# DSS_CTRL register map
Vendor: Texas Instruments
Peripheral module from a debugger description file (folder awr29xx).
Registers are 32-bit, read-only, no defined reset value unless marked. A register's access mark holds for its fields unless they carry their own. Offsets are as the file gives them; lines under a group give offsets from that group; [hi:lo] are bit positions; {n}, {i} and the like mark numbered series; 'fields as' and 'values as' point back to an identical list; <NAME> marks a mode.

## DSS_CTRL (part 1 of 2)
0xC8 DSS_TPCC_A_PARITY_STATUS
  [7:0] parity_addr — TPCC Error Address at which Parity Error occurred
0xCC DSS_TPCC_B_PARITY_STATUS
  fields as DSS_TPCC_A_PARITY_STATUS
0xD0 DSS_TPCC_C_PARITY_STATUS
  [8:0] parity_addr — TPCC Error Address at which Parity Error occurred
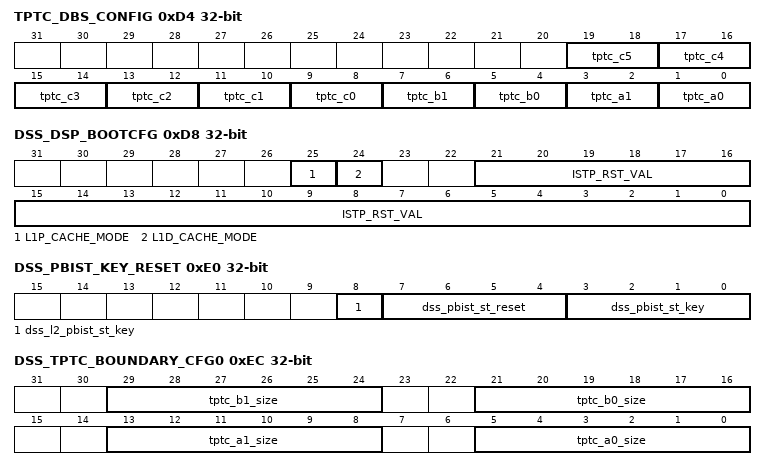
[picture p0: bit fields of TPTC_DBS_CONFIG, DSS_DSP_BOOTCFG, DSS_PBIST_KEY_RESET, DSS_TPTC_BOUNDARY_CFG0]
0xD4 TPTC_DBS_CONFIG rw
  [2n+9:2n+8] tptc_c{n} (n=0..5) — Max Burst size tieoff value for TPTC C{n}
  [7:6] tptc_b1 — Max Burst size tieoff value for TPTC B0
  [5:4] tptc_b0 — Max Burst size tieoff value for TPTC B0
  [3:2] tptc_a1 — Max Burst size tieoff value for TPTC A1
  [1:0] tptc_a0 — Max Burst size tieoff value for TPTC A0
0xD8 DSS_DSP_BOOTCFG rw
  [25] L1P_CACHE_MODE — DSP Boot Configuration : L1P Cache Mode
  [24] L1D_CACHE_MODE — DSP Boot Configuration : L1D Cache Mode
  [21:0] ISTP_RST_VAL — DSP Boot Configuration : Reset Vector
0xDC DSS_DSP_NMI_GATE rw
  [2:0] gate — Write 3'b111 to gate the Non Maskable Interrupt to the DSP. This is not expected to be used
0xE0 DSS_PBIST_KEY_RESET rw
  [8] dss_l2_pbist_st_key — DSS L2 PBIST Selftest Key.
  [7:4] dss_pbist_st_reset — DSS PBIST controller will be brought out of reset when value is 0xA
  [3:0] dss_pbist_st_key — DSS PBIST Selftest Key. Valid value is 0x5
0xE4 DSS_PBIST_REG0 rw
  [31:0] dss_pbist_reg0 — DSP PBIST registers
0xE8 DSS_PBIST_REG1 rw
  [31:0] dss_pbist_reg1 — DSP PBIST registers
0xEC DSS_TPTC_BOUNDARY_CFG0 rw
  [29:24] tptc_b1_size — 6 bit signal used for deciding the boundary crossing size for CID-RID-SID reordering of TPTC Example: writing 6'd19 decidies boundary to be 2^19 i.e. 512 KB
  [21:16] tptc_b0_size — 6 bit signal used for deciding the boundary crossing size for CID-RID-SID reordering of TPTC Example: writing 6'd19 decidies boundary to be 2^19 i.e. 512 KB
  [13:8] tptc_a1_size — 6 bit signal used for deciding the boundary crossing size for CID-RID-SID reordering of TPTC Example: writing 6'd19 decidies boundary to be 2^19 i.e. 512 KB
  [5:0] tptc_a0_size — 6 bit signal used for deciding the boundary crossing size for CID-RID-SID reordering of TPTC Example: writing 6'd19 decidies boundary to be 2^19 i.e. 512 KB
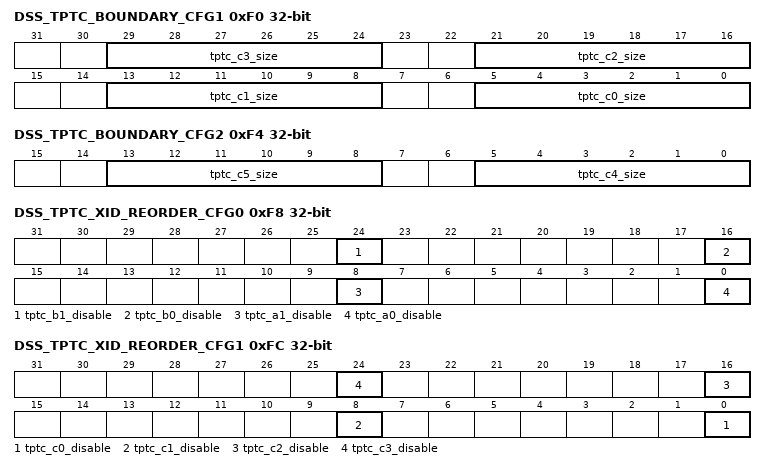
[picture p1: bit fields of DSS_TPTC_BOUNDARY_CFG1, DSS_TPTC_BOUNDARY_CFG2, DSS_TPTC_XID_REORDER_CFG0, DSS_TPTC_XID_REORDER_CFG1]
0xF0 DSS_TPTC_BOUNDARY_CFG1 rw
  [8n+5:8n] tptc_c{n}_size (n=0..3) — 6 bit signal used for deciding the boundary crossing size for CID-RID-SID reordering of TPTC Example: writing 6'd19 decidies boundary to be 2^19 i.e. 512 KB
0xF4 DSS_TPTC_BOUNDARY_CFG2 rw
  [13:8] tptc_c5_size — 6 bit signal used for deciding the boundary crossing size for CID-RID-SID reordering of TPTC Example: writing 6'd19 decidies boundary to be 2^19 i.e. 512 KB
  [5:0] tptc_c4_size — 6 bit signal used for deciding the boundary crossing size for CID-RID-SID reordering of TPTC Example: writing 6'd19 decidies boundary to be 2^19 i.e. 512 KB
0xF8 DSS_TPTC_XID_REORDER_CFG0 rw
  [24] tptc_b1_disable — Writing 1'b1 will disable the CID-RID-SID reodering feature for the TPTC instance
  [16] tptc_b0_disable — Writing 1'b1 will disable the CID-RID-SID reodering feature for the TPTC instance
  [8] tptc_a1_disable — Writing 1'b1 will disable the CID-RID-SID reodering feature for the TPTC instance
  [0] tptc_a0_disable — Writing 1'b1 will disable the CID-RID-SID reodering feature for the TPTC instance
0xFC DSS_TPTC_XID_REORDER_CFG1 rw
  [8n] tptc_c{n}_disable (n=0..3) — Writing 1'b1 will disable the CID-RID-SID reodering feature for the TPTC instance
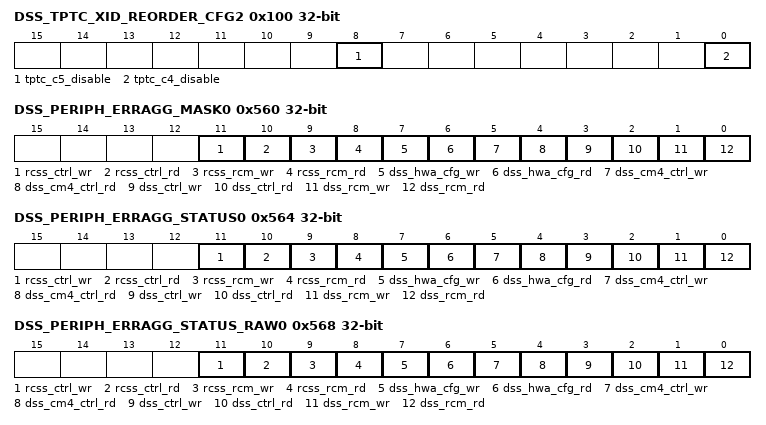
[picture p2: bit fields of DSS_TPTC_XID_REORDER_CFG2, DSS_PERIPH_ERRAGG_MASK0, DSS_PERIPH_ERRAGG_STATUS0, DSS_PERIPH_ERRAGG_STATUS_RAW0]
0x100 DSS_TPTC_XID_REORDER_CFG2 rw
  [8] tptc_c5_disable — Writing 1'b1 will disable the CID-RID-SID reodering feature for the TPTC instance
  [0] tptc_c4_disable — Writing 1'b1 will disable the CID-RID-SID reodering feature for the TPTC instance
{0x108+4i} ESM_GATING{i} rw (i=0..3)
  [31:0] esm_gating — Bit3:0 : writing '000' will ungate the DSS ESM Group2 Error {8i} Bit7:4 : writing '000' will ungate the DSS ESM Group2 Error {8i+1} Bit31:28 : writing '000' will ungate the DSS ESM Group2 Error {8i+7}
0x560 DSS_PERIPH_ERRAGG_MASK0 rw
  [11] rcss_ctrl_wr — Mask the Write error from RCSS_CTRL space from generating an error DSS_PERIPH_ERRAGG to the Processor
  [10] rcss_ctrl_rd — Mask the Read error from RCSS_CTRL space from generating an error DSS_PERIPH_ERRAGG to the Processor
  [9] rcss_rcm_wr — Mask the Write error from RCSS_RCM space from generating an error DSS_PERIPH_ERRAGG to the Processor
  [8] rcss_rcm_rd — Mask the Read error from RCSS_RCM space from generating an error DSS_PERIPH_ERRAGG to the Processor
  [7] dss_hwa_cfg_wr — Mask the Write error from DSS_HWA_CFG space from generating an error DSS_PERIPH_ERRAGG to the Processor
  [6] dss_hwa_cfg_rd — Mask the Read error from DSS_HWA_CFG space from generating an error DSS_PERIPH_ERRAGG to the Processor
  [5] dss_cm4_ctrl_wr — Mask the Write error from DSS_CM4_CTRL space from generating an error DSS_PERIPH_ERRAGG to the Processor
  [4] dss_cm4_ctrl_rd — Mask the Read error from DSS_CM4_CTRL space from generating an error DSS_PERIPH_ERRAGG to the Processor
  [3] dss_ctrl_wr — Mask the Write error from DSS_CTRL space from generating an error DSS_PERIPH_ERRAGG to the Processor
  [2] dss_ctrl_rd — Mask the Read error from DSS_CTRL space from generating an error DSS_PERIPH_ERRAGG to the Processor
  [1] dss_rcm_wr — Mask the Write error from DSS_RCM space from generating an error DSS_PERIPH_ERRAGG to the Processor
  [0] dss_rcm_rd — Mask the Read error from DSS_RCM space from generating an error DSS_PERIPH_ERRAGG to the Processor
0x564 DSS_PERIPH_ERRAGG_STATUS0 rw
  [11] rcss_ctrl_wr — Status of the Write error from RCSS_CTRL space. Read 1 : Read error occurred on access to the RCSS_CTRL space
  [10] rcss_ctrl_rd — Status of the Read error from RCSS_CTRL space. Read 1 : Read error occurred on access to the RCSS_CTRL space
  [9] rcss_rcm_wr — Status of the Write error from RCSS_RCM space. Read 1 : Read error occurred on access to the RCSS_RCM space
  [8] rcss_rcm_rd — Status of the Read error from RCSS_RCM space. Read 1 : Read error occurred on access to the RCSS_RCM space
  [7] dss_hwa_cfg_wr — Status of the Write error from DSS_HWA_CFG space. Read 1 : Read error occurred on access to the DSS_HWA_CFG space
  [6] dss_hwa_cfg_rd — Status of the Read error from DSS_HWA_CFG space. Read 1 : Read error occurred on access to the DSS_HWA_CFG space
  [5] dss_cm4_ctrl_wr — Status of the Write error from DSS_CM4_CTRL space. Read 1 : Read error occurred on access to the DSS_CM4_CTRL space
  [4] dss_cm4_ctrl_rd — Status of the Read error from DSS_CM4_CTRL space. Read 1 : Read error occurred on access to the DSS_CM4_CTRL space
  [3] dss_ctrl_wr — Status of the Write error from DSS_CTRL space. Read 1 : Read error occurred on access to the DSS_CTRL space
  [2] dss_ctrl_rd — Status of the Read error from DSS_CTRL space. Read 1 : Read error occurred on access to the DSS_CTRL space
  [1] dss_rcm_wr — Status of the Write error from DSS_RCM space. Read 1 : Read error occurred on access to the DSS_RCM space
  [0] dss_rcm_rd — Status of the Read error from DSS_RCM space. Read 1 : Read error occurred on access to the DSS_RCM space
0x568 DSS_PERIPH_ERRAGG_STATUS_RAW0 rw
  [11] rcss_ctrl_wr — Raw Status of the Write error from RCSS_CTRL space irrespective of it being masked. Read 1 : Read error occurred on access to the RCSS_CTRL space
  [10] rcss_ctrl_rd — Raw Status of the Read error from RCSS_CTRL space irrespective of it being masked. Read 1 : Read error occurred on access to the RCSS_CTRL space
  [9] rcss_rcm_wr — Raw Status of the Write error from RCSS_RCM space irrespective of it being masked. Read 1 : Read error occurred on access to the RCSS_RCM space
  [8] rcss_rcm_rd — Raw Status of the Read error from RCSS_RCM space irrespective of it being masked. Read 1 : Read error occurred on access to the RCSS_RCM space
  [7] dss_hwa_cfg_wr — Raw Status of the Write error from DSS_HWA_CFG space irrespective of it being masked. Read 1 : Read error occurred on access to the DSS_HWA_CFG space
  [6] dss_hwa_cfg_rd — Raw Status of the Read error from DSS_HWA_CFG space irrespective of it being masked. Read 1 : Read error occurred on access to the DSS_HWA_CFG space
  [5] dss_cm4_ctrl_wr — Raw Status of the Write error from DSS_CM4_CTRL space irrespective of it being masked. Read 1 : Read error occurred on access to the DSS_CM4_CTRL space
  [4] dss_cm4_ctrl_rd — Raw Status of the Read error from DSS_CM4_CTRL space irrespective of it being masked. Read 1 : Read error occurred on access to the DSS_CM4_CTRL space
  [3] dss_ctrl_wr — Raw Status of the Write error from DSS_CTRL space irrespective of it being masked. Read 1 : Read error occurred on access to the DSS_CTRL space
  [2] dss_ctrl_rd — Raw Status of the Read error from DSS_CTRL space irrespective of it being masked. Read 1 : Read error occurred on access to the DSS_CTRL space
  [1] dss_rcm_wr — Raw Status of the Write error from DSS_RCM space irrespective of it being masked. Read 1 : Read error occurred on access to the DSS_RCM space
  [0] dss_rcm_rd — Raw Status of the Read error from DSS_RCM space irrespective of it being masked. Read 1 : Read error occurred on access to the DSS_RCM space
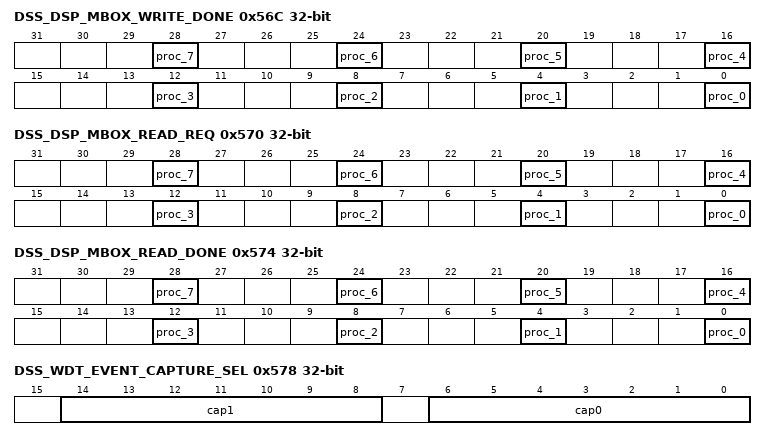
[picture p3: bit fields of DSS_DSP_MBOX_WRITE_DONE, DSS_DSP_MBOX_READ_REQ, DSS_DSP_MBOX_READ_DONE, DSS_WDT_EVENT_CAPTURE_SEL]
0x56C DSS_DSP_MBOX_WRITE_DONE rw
  [28] proc_7 — Write pulse bit field:This register should be written once finishing writing into the mailbox memory of processor 7
  [4n] proc_{n} (n=0..6) — Write pulse bit field: This register should be written once finishing writing into the mailbox memory of processor {n}
0x570 DSS_DSP_MBOX_READ_REQ rw
  [4n] proc_{n} (n=0..7) — This is request from processor {n} to DSS_DSP. Requesting it to read from mailbox.
0x574 DSS_DSP_MBOX_READ_DONE rw
  [4n] proc_{n} (n=0..7) — This register should be written once finishing reading from DSS_DSP's mailbox written by proc {n}
0x578 DSS_WDT_EVENT_CAPTURE_SEL rw
  [14:8] cap1 — Select the DSS_WDT Capture Event 1 from the DSS DSP Interrupt Map
  [6:0] cap0 — Select the DSS_WDT Capture Event 0 from the DSS DSP Interrupt Map
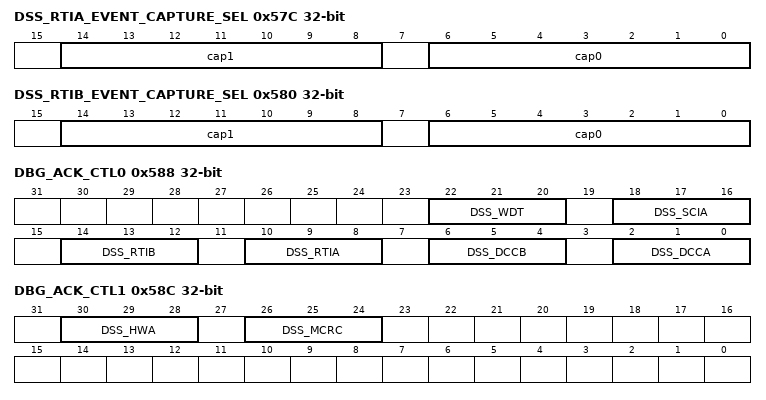
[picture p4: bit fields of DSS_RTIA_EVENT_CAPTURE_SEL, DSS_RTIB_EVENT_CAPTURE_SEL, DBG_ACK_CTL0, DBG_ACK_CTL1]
0x57C DSS_RTIA_EVENT_CAPTURE_SEL rw
  [14:8] cap1 — Select the DSS_RTIA Capture Event 1 from the DSS DSP Interrupt Map
  [6:0] cap0 — Select the DSS_RTIA Capture Event 0 from the DSS DSP Interrupt Map
0x580 DSS_RTIB_EVENT_CAPTURE_SEL rw
  [14:8] cap1 — Select the DSS_RTIB Capture Event 1 from the DSS DSP Interrupt Map
  [6:0] cap0 — Select the DSS_RTIB Capture Event 0 from the DSS DSP Interrupt Map
0x584 DBG_ACK_CPU_CTRL rw
  [0] sel — Select the Processor Suspend that is used to Suspend the DSS Peripehrals 0: DSP 1:MSS CR5
0x588 DBG_ACK_CTL0 rw
  [22:20] DSS_WDT — Enable Suspend control for the peripheral. 0 :Peripheral not suspended along with processor 1: Peripehal Suspended along with procesor
  [18:16] DSS_SCIA — Enable Suspend control for the peripheral. 0 :Peripheral not suspended along with processor 1: Peripehal Suspended along with procesor
  [14:12] DSS_RTIB — Enable Suspend control for the peripheral. 0 :Peripheral not suspended along with processor 1: Peripehal Suspended along with procesor
  [10:8] DSS_RTIA — Enable Suspend control for the peripheral. 0 :Peripheral not suspended along with processor 1: Peripehal Suspended along with procesor
  [6:4] DSS_DCCB — Enable Suspend control for the peripheral. 0 :Peripheral not suspended along with processor 1: Peripehal Suspended along with procesor
  [2:0] DSS_DCCA — Enable Suspend control for the peripheral. 0 :Peripheral not suspended along with processor 1: Peripehal Suspended along with procesor
0x58C DBG_ACK_CTL1 rw
  [30:28] DSS_HWA — Enable Suspend control for the peripheral. 0 :Peripheral not suspended along with processor 1: Peripehal Suspended along with procesor
  [26:24] DSS_MCRC — Enable Suspend control for the peripheral. 0 :Peripheral not suspended along with processor 1: Peripehal Suspended along with procesor
0x590 DSS_DSP_INT_SEL rw
  [2:0] RCSS_CSI2_ICSSM — DSS DSP Interrupt selcet 0x0: CSI2 Interrupts are propagated to DSP 0x7 : ICSSM Interrupts are propagted to DSP
0x594 DSS_CBUFF_TRIGGER_SEL rw
  [6:0] sel — DSS CBUFF HW Trigger select from DSS DSP Interrupt Map. Reset value selects RSS_ADC_CAPTURE_COMPLETE as cbuff trigger
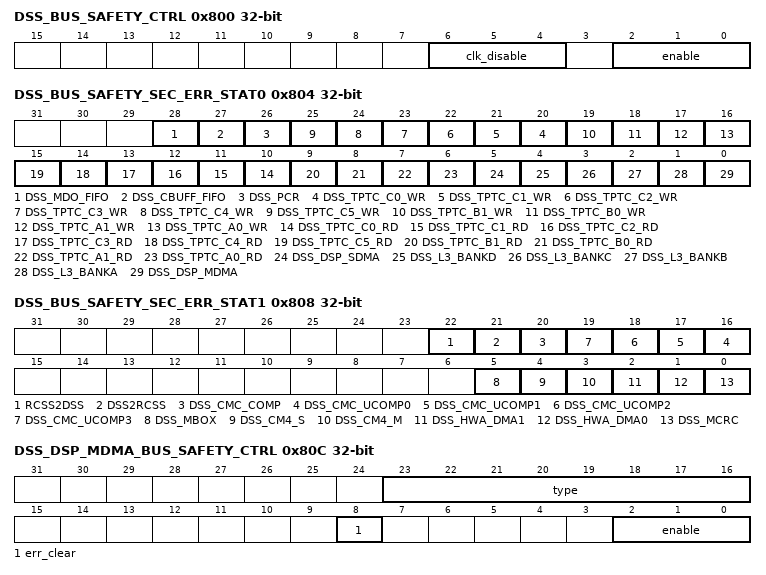
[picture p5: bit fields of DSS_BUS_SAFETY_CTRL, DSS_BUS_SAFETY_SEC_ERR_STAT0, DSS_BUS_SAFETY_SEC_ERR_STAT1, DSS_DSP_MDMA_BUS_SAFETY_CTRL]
0x800 DSS_BUS_SAFETY_CTRL rw
  [6:4] clk_disable — Option to clock gate the safety infrastructure is Safety is disabled
  [2:0] enable — Refer to TPR12 Substem Microarch document for more details
0x804 DSS_BUS_SAFETY_SEC_ERR_STAT0
  [28] DSS_MDO_FIFO — Refer to TPR12 Substem Microarch document for more details
  [27] DSS_CBUFF_FIFO — Refer to TPR12 Substem Microarch document for more details
  [26] DSS_PCR — Refer to TPR12 Substem Microarch document for more details
  [n+20] DSS_TPTC_C{n}_WR (n=0..5) — Refer to TPR12 Substem Microarch document for more details
  [19] DSS_TPTC_B1_WR — Refer to TPR12 Substem Microarch document for more details
  [18] DSS_TPTC_B0_WR — Refer to TPR12 Substem Microarch document for more details
  [17] DSS_TPTC_A1_WR — Refer to TPR12 Substem Microarch document for more details
  [16] DSS_TPTC_A0_WR — Refer to TPR12 Substem Microarch document for more details
  [n+10] DSS_TPTC_C{n}_RD (n=0..5) — Refer to TPR12 Substem Microarch document for more details
  [9] DSS_TPTC_B1_RD — Refer to TPR12 Substem Microarch document for more details
  [8] DSS_TPTC_B0_RD — Refer to TPR12 Substem Microarch document for more details
  [7] DSS_TPTC_A1_RD — Refer to TPR12 Substem Microarch document for more details
  [6] DSS_TPTC_A0_RD — Refer to TPR12 Substem Microarch document for more details
  [5] DSS_DSP_SDMA — Refer to TPR12 Substem Microarch document for more details
  [4] DSS_L3_BANKD — Refer to TPR12 Substem Microarch document for more details
  [3] DSS_L3_BANKC — Refer to TPR12 Substem Microarch document for more details
  [2] DSS_L3_BANKB — Refer to TPR12 Substem Microarch document for more details
  [1] DSS_L3_BANKA — Refer to TPR12 Substem Microarch document for more details
  [0] DSS_DSP_MDMA — Refer to TPR12 Substem Microarch document for more details
0x808 DSS_BUS_SAFETY_SEC_ERR_STAT1
  [22] RCSS2DSS — Refer to TPR12 Substem Microarch document for more details
  [21] DSS2RCSS — Refer to TPR12 Substem Microarch document for more details
  [20] DSS_CMC_COMP — Refer to TPR12 Substem Microarch document for more details
  [n+16] DSS_CMC_UCOMP{n} (n=0..3) — Refer to TPR12 Substem Microarch document for more details
  [5] DSS_MBOX — Refer to TPR12 Substem Microarch document for more details
  [4] DSS_CM4_S — Refer to TPR12 Substem Microarch document for more details
  [3] DSS_CM4_M — Refer to TPR12 Substem Microarch document for more details
  [2] DSS_HWA_DMA1 — Refer to TPR12 Substem Microarch document for more details
  [1] DSS_HWA_DMA0 — Refer to TPR12 Substem Microarch document for more details
  [0] DSS_MCRC — Refer to TPR12 Substem Microarch document for more details
0x80C DSS_DSP_MDMA_BUS_SAFETY_CTRL access per field
  [23:16] type ro — Refer to TPR12 Substem Microarch document for more details
  [8] err_clear rw — Refer to TPR12 Substem Microarch document for more details
  [2:0] enable rw — Refer to TPR12 Substem Microarch document for more details
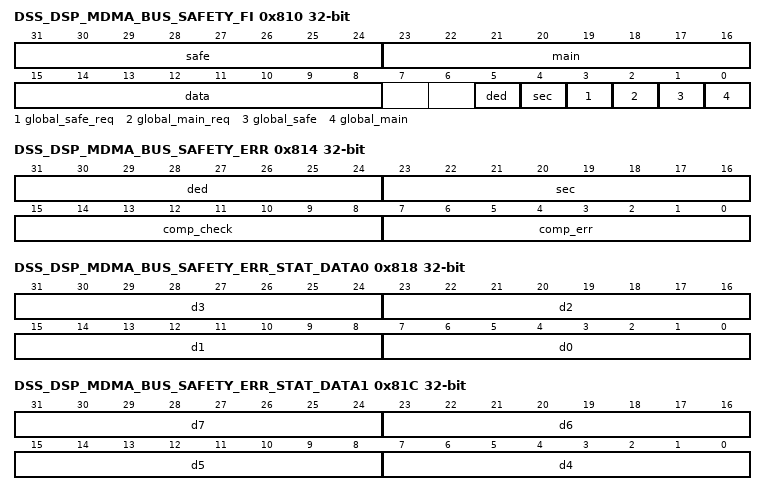
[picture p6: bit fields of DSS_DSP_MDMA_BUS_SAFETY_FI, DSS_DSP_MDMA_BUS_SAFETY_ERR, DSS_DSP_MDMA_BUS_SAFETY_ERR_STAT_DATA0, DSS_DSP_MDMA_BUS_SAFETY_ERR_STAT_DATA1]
0x810 DSS_DSP_MDMA_BUS_SAFETY_FI rw
  [31:24] safe — Refer to TPR12 Substem Microarch document for more details
  [23:16] main — Refer to TPR12 Substem Microarch document for more details
  [15:8] data — Refer to TPR12 Substem Microarch document for more details
  [5] ded — Refer to TPR12 Substem Microarch document for more details
  [4] sec — Refer to TPR12 Substem Microarch document for more details
  [3] global_safe_req — Refer to TPR12 Substem Microarch document for more details
  [2] global_main_req — Refer to TPR12 Substem Microarch document for more details
  [1] global_safe — Refer to TPR12 Substem Microarch document for more details
  [0] global_main — Refer to TPR12 Substem Microarch document for more details
0x814 DSS_DSP_MDMA_BUS_SAFETY_ERR
  [31:24] ded — Refer to TPR12 Substem Microarch document for more details
  [23:16] sec — Refer to TPR12 Substem Microarch document for more details
  [15:8] comp_check — Refer to TPR12 Substem Microarch document for more details
  [7:0] comp_err — Refer to TPR12 Substem Microarch document for more details
0x818 DSS_DSP_MDMA_BUS_SAFETY_ERR_STAT_DATA0
  [8n+7:8n] d{n} (n=0..3) — Refer to TPR12 Substem Microarch document for more details
0x81C DSS_DSP_MDMA_BUS_SAFETY_ERR_STAT_DATA1
  [8n-25:8n-32] d{n} (n=4..7) — Refer to TPR12 Substem Microarch document for more details
0x820 DSS_DSP_MDMA_BUS_SAFETY_ERR_STAT_CMD
  [31:0] stat — Refer to TPR12 Substem Microarch document for more details
0x824 DSS_DSP_MDMA_BUS_SAFETY_ERR_STAT_WRITE
  fields as DSS_DSP_MDMA_BUS_SAFETY_ERR_STAT_CMD
0x828 DSS_DSP_MDMA_BUS_SAFETY_ERR_STAT_READ
  fields as DSS_DSP_MDMA_BUS_SAFETY_ERR_STAT_CMD
0x82C DSS_DSP_MDMA_BUS_SAFETY_ERR_STAT_WRITERESP
  fields as DSS_DSP_MDMA_BUS_SAFETY_ERR_STAT_CMD
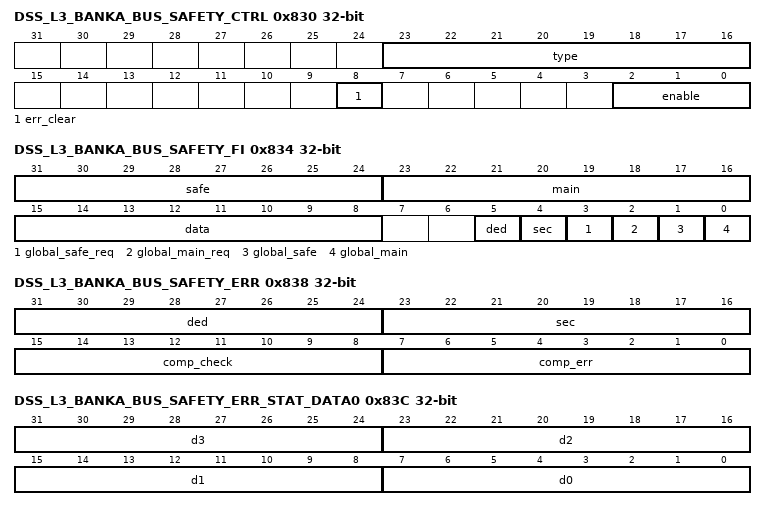
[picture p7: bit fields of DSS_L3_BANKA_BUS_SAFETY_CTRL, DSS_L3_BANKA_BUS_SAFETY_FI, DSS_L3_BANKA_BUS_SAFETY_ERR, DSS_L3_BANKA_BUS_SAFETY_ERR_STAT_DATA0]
0x830 DSS_L3_BANKA_BUS_SAFETY_CTRL access per field
  fields as DSS_DSP_MDMA_BUS_SAFETY_CTRL
0x834 DSS_L3_BANKA_BUS_SAFETY_FI rw
  fields as DSS_DSP_MDMA_BUS_SAFETY_FI
0x838 DSS_L3_BANKA_BUS_SAFETY_ERR
  fields as DSS_DSP_MDMA_BUS_SAFETY_ERR
0x83C DSS_L3_BANKA_BUS_SAFETY_ERR_STAT_DATA0
  fields as DSS_DSP_MDMA_BUS_SAFETY_ERR_STAT_DATA0
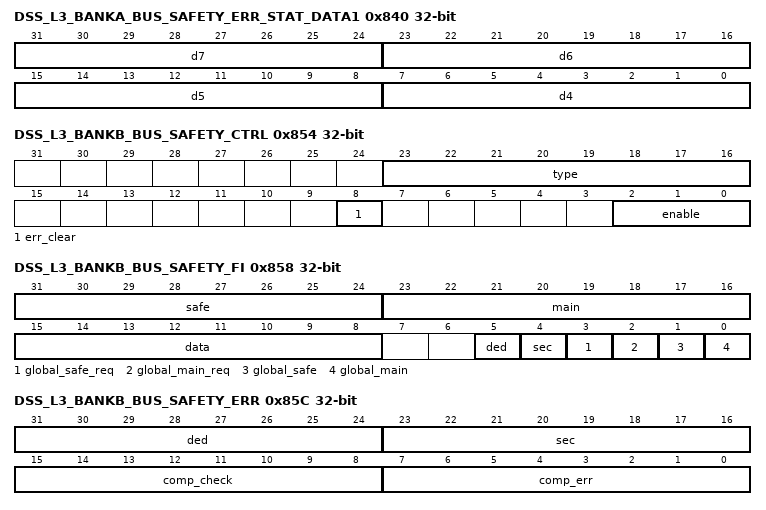
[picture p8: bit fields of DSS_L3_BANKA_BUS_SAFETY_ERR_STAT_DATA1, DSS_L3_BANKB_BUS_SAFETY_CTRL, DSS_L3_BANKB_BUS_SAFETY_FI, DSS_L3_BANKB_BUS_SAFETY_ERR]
0x840 DSS_L3_BANKA_BUS_SAFETY_ERR_STAT_DATA1
  fields as DSS_DSP_MDMA_BUS_SAFETY_ERR_STAT_DATA1
0x844 DSS_L3_BANKA_BUS_SAFETY_ERR_STAT_CMD
  fields as DSS_DSP_MDMA_BUS_SAFETY_ERR_STAT_CMD
0x848 DSS_L3_BANKA_BUS_SAFETY_ERR_STAT_WRITE
  fields as DSS_DSP_MDMA_BUS_SAFETY_ERR_STAT_CMD
0x84C DSS_L3_BANKA_BUS_SAFETY_ERR_STAT_READ
  fields as DSS_DSP_MDMA_BUS_SAFETY_ERR_STAT_CMD
0x850 DSS_L3_BANKA_BUS_SAFETY_ERR_STAT_WRITERESP
  fields as DSS_DSP_MDMA_BUS_SAFETY_ERR_STAT_CMD
0x854 DSS_L3_BANKB_BUS_SAFETY_CTRL access per field
  fields as DSS_DSP_MDMA_BUS_SAFETY_CTRL
0x858 DSS_L3_BANKB_BUS_SAFETY_FI rw
  fields as DSS_DSP_MDMA_BUS_SAFETY_FI
0x85C DSS_L3_BANKB_BUS_SAFETY_ERR
  fields as DSS_DSP_MDMA_BUS_SAFETY_ERR
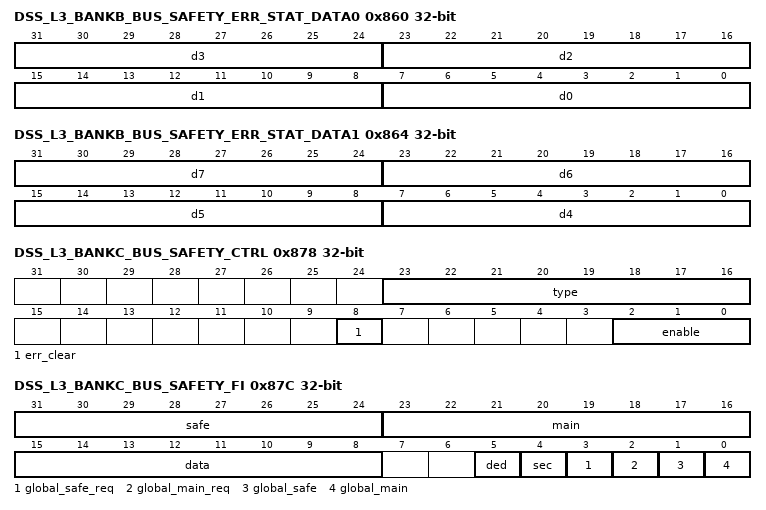
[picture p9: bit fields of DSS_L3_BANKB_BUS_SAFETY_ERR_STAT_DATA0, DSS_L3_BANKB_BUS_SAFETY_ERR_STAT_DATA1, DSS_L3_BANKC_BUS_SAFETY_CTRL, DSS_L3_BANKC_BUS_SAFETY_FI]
0x860 DSS_L3_BANKB_BUS_SAFETY_ERR_STAT_DATA0
  fields as DSS_DSP_MDMA_BUS_SAFETY_ERR_STAT_DATA0
0x864 DSS_L3_BANKB_BUS_SAFETY_ERR_STAT_DATA1
  fields as DSS_DSP_MDMA_BUS_SAFETY_ERR_STAT_DATA1
0x868 DSS_L3_BANKB_BUS_SAFETY_ERR_STAT_CMD
  fields as DSS_DSP_MDMA_BUS_SAFETY_ERR_STAT_CMD
0x86C DSS_L3_BANKB_BUS_SAFETY_ERR_STAT_WRITE
  fields as DSS_DSP_MDMA_BUS_SAFETY_ERR_STAT_CMD
0x870 DSS_L3_BANKB_BUS_SAFETY_ERR_STAT_READ
  fields as DSS_DSP_MDMA_BUS_SAFETY_ERR_STAT_CMD
0x874 DSS_L3_BANKB_BUS_SAFETY_ERR_STAT_WRITERESP
  fields as DSS_DSP_MDMA_BUS_SAFETY_ERR_STAT_CMD
0x878 DSS_L3_BANKC_BUS_SAFETY_CTRL access per field
  fields as DSS_DSP_MDMA_BUS_SAFETY_CTRL
0x87C DSS_L3_BANKC_BUS_SAFETY_FI rw
  fields as DSS_DSP_MDMA_BUS_SAFETY_FI
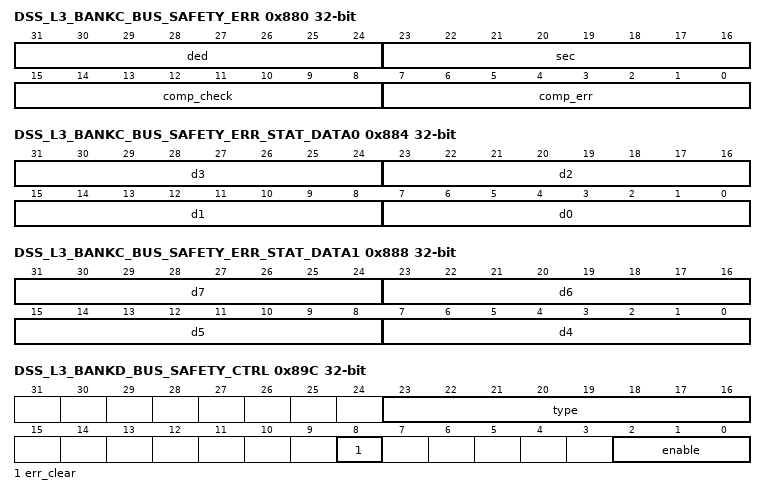
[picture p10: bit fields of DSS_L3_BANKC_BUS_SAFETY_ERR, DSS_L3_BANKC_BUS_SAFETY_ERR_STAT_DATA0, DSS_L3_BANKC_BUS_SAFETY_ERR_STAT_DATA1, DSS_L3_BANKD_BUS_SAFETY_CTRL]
0x880 DSS_L3_BANKC_BUS_SAFETY_ERR
  fields as DSS_DSP_MDMA_BUS_SAFETY_ERR
0x884 DSS_L3_BANKC_BUS_SAFETY_ERR_STAT_DATA0
  fields as DSS_DSP_MDMA_BUS_SAFETY_ERR_STAT_DATA0
0x888 DSS_L3_BANKC_BUS_SAFETY_ERR_STAT_DATA1
  fields as DSS_DSP_MDMA_BUS_SAFETY_ERR_STAT_DATA1
0x88C DSS_L3_BANKC_BUS_SAFETY_ERR_STAT_CMD
  fields as DSS_DSP_MDMA_BUS_SAFETY_ERR_STAT_CMD
0x890 DSS_L3_BANKC_BUS_SAFETY_ERR_STAT_WRITE
  fields as DSS_DSP_MDMA_BUS_SAFETY_ERR_STAT_CMD
0x894 DSS_L3_BANKC_BUS_SAFETY_ERR_STAT_READ
  fields as DSS_DSP_MDMA_BUS_SAFETY_ERR_STAT_CMD
0x898 DSS_L3_BANKC_BUS_SAFETY_ERR_STAT_WRITERESP
  fields as DSS_DSP_MDMA_BUS_SAFETY_ERR_STAT_CMD
0x89C DSS_L3_BANKD_BUS_SAFETY_CTRL access per field
  fields as DSS_DSP_MDMA_BUS_SAFETY_CTRL
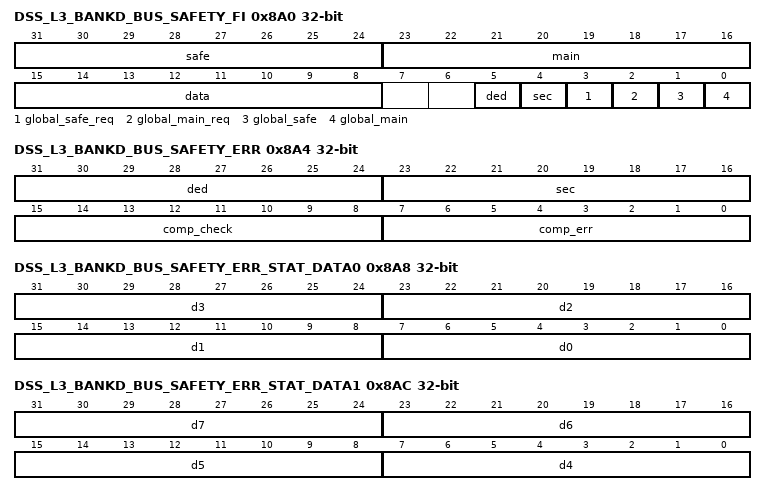
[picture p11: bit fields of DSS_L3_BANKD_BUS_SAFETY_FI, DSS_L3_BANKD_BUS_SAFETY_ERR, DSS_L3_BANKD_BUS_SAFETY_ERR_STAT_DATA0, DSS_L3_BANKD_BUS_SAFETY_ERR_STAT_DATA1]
0x8A0 DSS_L3_BANKD_BUS_SAFETY_FI rw
  fields as DSS_DSP_MDMA_BUS_SAFETY_FI
0x8A4 DSS_L3_BANKD_BUS_SAFETY_ERR
  fields as DSS_DSP_MDMA_BUS_SAFETY_ERR
0x8A8 DSS_L3_BANKD_BUS_SAFETY_ERR_STAT_DATA0
  fields as DSS_DSP_MDMA_BUS_SAFETY_ERR_STAT_DATA0
0x8AC DSS_L3_BANKD_BUS_SAFETY_ERR_STAT_DATA1
  fields as DSS_DSP_MDMA_BUS_SAFETY_ERR_STAT_DATA1
0x8B0 DSS_L3_BANKD_BUS_SAFETY_ERR_STAT_CMD
  fields as DSS_DSP_MDMA_BUS_SAFETY_ERR_STAT_CMD
0x8B4 DSS_L3_BANKD_BUS_SAFETY_ERR_STAT_WRITE
  fields as DSS_DSP_MDMA_BUS_SAFETY_ERR_STAT_CMD
0x8B8 DSS_L3_BANKD_BUS_SAFETY_ERR_STAT_READ
  fields as DSS_DSP_MDMA_BUS_SAFETY_ERR_STAT_CMD
0x8BC DSS_L3_BANKD_BUS_SAFETY_ERR_STAT_WRITERESP
  fields as DSS_DSP_MDMA_BUS_SAFETY_ERR_STAT_CMD
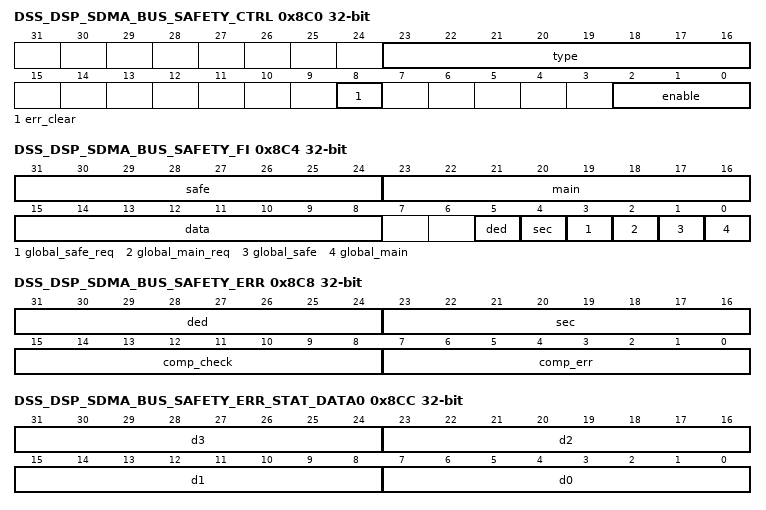
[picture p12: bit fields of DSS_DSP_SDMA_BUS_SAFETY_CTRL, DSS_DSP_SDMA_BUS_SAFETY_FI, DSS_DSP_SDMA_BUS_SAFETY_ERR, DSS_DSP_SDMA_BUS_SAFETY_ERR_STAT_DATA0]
0x8C0 DSS_DSP_SDMA_BUS_SAFETY_CTRL access per field
  fields as DSS_DSP_MDMA_BUS_SAFETY_CTRL
0x8C4 DSS_DSP_SDMA_BUS_SAFETY_FI rw
  fields as DSS_DSP_MDMA_BUS_SAFETY_FI
0x8C8 DSS_DSP_SDMA_BUS_SAFETY_ERR
  fields as DSS_DSP_MDMA_BUS_SAFETY_ERR
0x8CC DSS_DSP_SDMA_BUS_SAFETY_ERR_STAT_DATA0
  fields as DSS_DSP_MDMA_BUS_SAFETY_ERR_STAT_DATA0
0x8D0 DSS_DSP_SDMA_BUS_SAFETY_ERR_STAT_CMD
  fields as DSS_DSP_MDMA_BUS_SAFETY_ERR_STAT_CMD
0x8D4 DSS_DSP_SDMA_BUS_SAFETY_ERR_STAT_WRITE
  fields as DSS_DSP_MDMA_BUS_SAFETY_ERR_STAT_CMD
0x8D8 DSS_DSP_SDMA_BUS_SAFETY_ERR_STAT_READ
  fields as DSS_DSP_MDMA_BUS_SAFETY_ERR_STAT_CMD
0x8DC DSS_DSP_SDMA_BUS_SAFETY_ERR_STAT_WRITERESP
  fields as DSS_DSP_MDMA_BUS_SAFETY_ERR_STAT_CMD
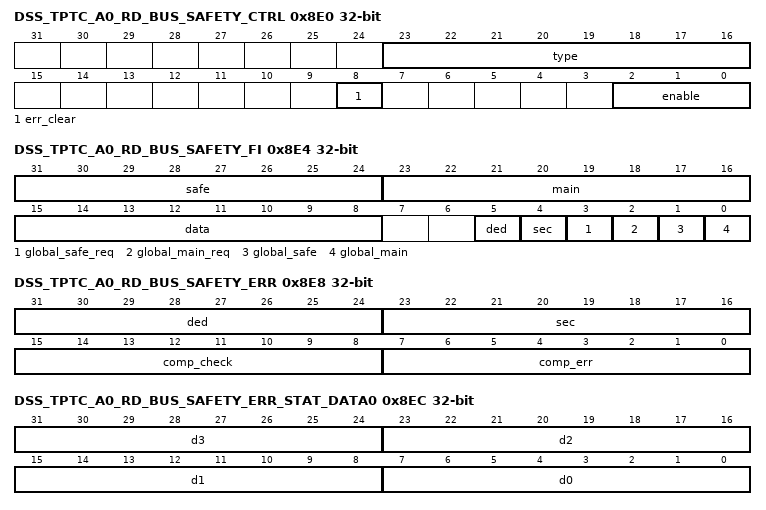
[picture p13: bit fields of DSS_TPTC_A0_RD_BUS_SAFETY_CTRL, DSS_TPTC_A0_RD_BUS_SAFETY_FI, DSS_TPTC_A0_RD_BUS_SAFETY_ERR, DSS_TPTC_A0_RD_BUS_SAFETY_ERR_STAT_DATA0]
0x8E0 DSS_TPTC_A0_RD_BUS_SAFETY_CTRL access per field
  fields as DSS_DSP_MDMA_BUS_SAFETY_CTRL
0x8E4 DSS_TPTC_A0_RD_BUS_SAFETY_FI rw
  fields as DSS_DSP_MDMA_BUS_SAFETY_FI
0x8E8 DSS_TPTC_A0_RD_BUS_SAFETY_ERR
  fields as DSS_DSP_MDMA_BUS_SAFETY_ERR
0x8EC DSS_TPTC_A0_RD_BUS_SAFETY_ERR_STAT_DATA0
  fields as DSS_DSP_MDMA_BUS_SAFETY_ERR_STAT_DATA0
0x8F0 DSS_TPTC_A0_RD_BUS_SAFETY_ERR_STAT_CMD
  fields as DSS_DSP_MDMA_BUS_SAFETY_ERR_STAT_CMD
0x8F4 DSS_TPTC_A0_RD_BUS_SAFETY_ERR_STAT_READ
  fields as DSS_DSP_MDMA_BUS_SAFETY_ERR_STAT_CMD
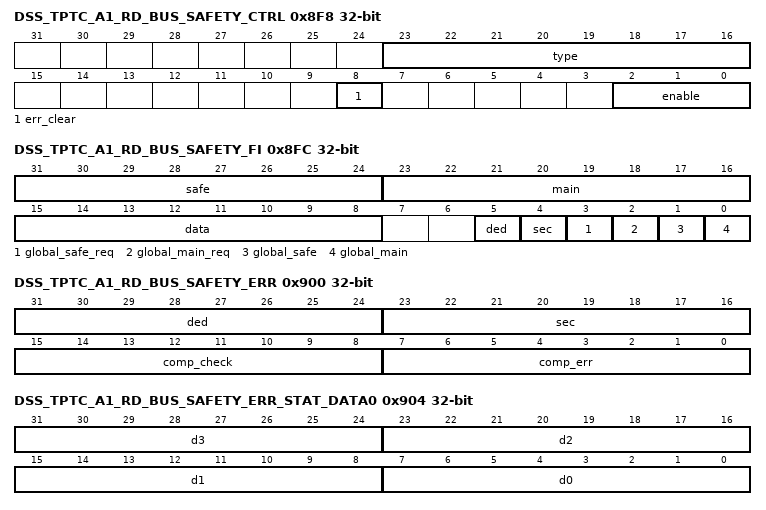
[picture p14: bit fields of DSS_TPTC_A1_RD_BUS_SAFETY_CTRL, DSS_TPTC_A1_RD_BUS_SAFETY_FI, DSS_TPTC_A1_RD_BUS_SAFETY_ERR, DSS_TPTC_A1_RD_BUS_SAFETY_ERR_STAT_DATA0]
0x8F8 DSS_TPTC_A1_RD_BUS_SAFETY_CTRL access per field
  fields as DSS_DSP_MDMA_BUS_SAFETY_CTRL
0x8FC DSS_TPTC_A1_RD_BUS_SAFETY_FI rw
  fields as DSS_DSP_MDMA_BUS_SAFETY_FI
0x900 DSS_TPTC_A1_RD_BUS_SAFETY_ERR
  fields as DSS_DSP_MDMA_BUS_SAFETY_ERR
0x904 DSS_TPTC_A1_RD_BUS_SAFETY_ERR_STAT_DATA0
  fields as DSS_DSP_MDMA_BUS_SAFETY_ERR_STAT_DATA0
0x908 DSS_TPTC_A1_RD_BUS_SAFETY_ERR_STAT_CMD
  fields as DSS_DSP_MDMA_BUS_SAFETY_ERR_STAT_CMD
0x90C DSS_TPTC_A1_RD_BUS_SAFETY_ERR_STAT_READ
  fields as DSS_DSP_MDMA_BUS_SAFETY_ERR_STAT_CMD
0x910 DSS_TPTC_B0_RD_BUS_SAFETY_CTRL access per field
  fields as DSS_DSP_MDMA_BUS_SAFETY_CTRL
0x914 DSS_TPTC_B0_RD_BUS_SAFETY_FI rw
  fields as DSS_DSP_MDMA_BUS_SAFETY_FI
0x918 DSS_TPTC_B0_RD_BUS_SAFETY_ERR
  fields as DSS_DSP_MDMA_BUS_SAFETY_ERR
0x91C DSS_TPTC_B0_RD_BUS_SAFETY_ERR_STAT_DATA0
  fields as DSS_DSP_MDMA_BUS_SAFETY_ERR_STAT_DATA0
0x920 DSS_TPTC_B0_RD_BUS_SAFETY_ERR_STAT_CMD
  fields as DSS_DSP_MDMA_BUS_SAFETY_ERR_STAT_CMD
0x924 DSS_TPTC_B0_RD_BUS_SAFETY_ERR_STAT_READ
  fields as DSS_DSP_MDMA_BUS_SAFETY_ERR_STAT_CMD
0x928 DSS_TPTC_B1_RD_BUS_SAFETY_CTRL access per field
  fields as DSS_DSP_MDMA_BUS_SAFETY_CTRL
0x92C DSS_TPTC_B1_RD_BUS_SAFETY_FI rw
  fields as DSS_DSP_MDMA_BUS_SAFETY_FI
0x930 DSS_TPTC_B1_RD_BUS_SAFETY_ERR
  fields as DSS_DSP_MDMA_BUS_SAFETY_ERR
0x934 DSS_TPTC_B1_RD_BUS_SAFETY_ERR_STAT_DATA0
  fields as DSS_DSP_MDMA_BUS_SAFETY_ERR_STAT_DATA0
0x938 DSS_TPTC_B1_RD_BUS_SAFETY_ERR_STAT_CMD
  fields as DSS_DSP_MDMA_BUS_SAFETY_ERR_STAT_CMD
0x93C DSS_TPTC_B1_RD_BUS_SAFETY_ERR_STAT_READ
  fields as DSS_DSP_MDMA_BUS_SAFETY_ERR_STAT_CMD
{0x940+0x18*i} DSS_TPTC_C{i}_RD_BUS_SAFETY_CTRL access per field (i=0..5)
  fields as DSS_DSP_MDMA_BUS_SAFETY_CTRL
{0x944+0x18*i} DSS_TPTC_C{i}_RD_BUS_SAFETY_FI rw (i=0..5)
  fields as DSS_DSP_MDMA_BUS_SAFETY_FI
{0x948+0x18*i} DSS_TPTC_C{i}_RD_BUS_SAFETY_ERR (i=0..5)
  fields as DSS_DSP_MDMA_BUS_SAFETY_ERR
{0x94C+0x18*i} DSS_TPTC_C{i}_RD_BUS_SAFETY_ERR_STAT_DATA0 (i=0..5)
  fields as DSS_DSP_MDMA_BUS_SAFETY_ERR_STAT_DATA0
{0x950+0x18*i} DSS_TPTC_C{i}_RD_BUS_SAFETY_ERR_STAT_CMD (i=0..5)
  fields as DSS_DSP_MDMA_BUS_SAFETY_ERR_STAT_CMD
{0x954+0x18*i} DSS_TPTC_C{i}_RD_BUS_SAFETY_ERR_STAT_READ (i=0..5)
  fields as DSS_DSP_MDMA_BUS_SAFETY_ERR_STAT_CMD
0x9D0 DSS_TPTC_A0_WR_BUS_SAFETY_CTRL access per field
  fields as DSS_DSP_MDMA_BUS_SAFETY_CTRL
0x9D4 DSS_TPTC_A0_WR_BUS_SAFETY_FI rw
  fields as DSS_DSP_MDMA_BUS_SAFETY_FI
0x9D8 DSS_TPTC_A0_WR_BUS_SAFETY_ERR
  fields as DSS_DSP_MDMA_BUS_SAFETY_ERR
0x9DC DSS_TPTC_A0_WR_BUS_SAFETY_ERR_STAT_DATA0
  fields as DSS_DSP_MDMA_BUS_SAFETY_ERR_STAT_DATA0
0x9E0 DSS_TPTC_A0_WR_BUS_SAFETY_ERR_STAT_CMD
  fields as DSS_DSP_MDMA_BUS_SAFETY_ERR_STAT_CMD
0x9E4 DSS_TPTC_A0_WR_BUS_SAFETY_ERR_STAT_WRITE
  fields as DSS_DSP_MDMA_BUS_SAFETY_ERR_STAT_CMD
0x9E8 DSS_TPTC_A0_WR_BUS_SAFETY_ERR_STAT_WRITERESP
  fields as DSS_DSP_MDMA_BUS_SAFETY_ERR_STAT_CMD
0x9EC DSS_TPTC_A1_WR_BUS_SAFETY_CTRL access per field
  fields as DSS_DSP_MDMA_BUS_SAFETY_CTRL
0x9F0 DSS_TPTC_A1_WR_BUS_SAFETY_FI rw
  fields as DSS_DSP_MDMA_BUS_SAFETY_FI
0x9F4 DSS_TPTC_A1_WR_BUS_SAFETY_ERR
  fields as DSS_DSP_MDMA_BUS_SAFETY_ERR
0x9F8 DSS_TPTC_A1_WR_BUS_SAFETY_ERR_STAT_DATA0
  fields as DSS_DSP_MDMA_BUS_SAFETY_ERR_STAT_DATA0
0x9FC DSS_TPTC_A1_WR_BUS_SAFETY_ERR_STAT_CMD
  fields as DSS_DSP_MDMA_BUS_SAFETY_ERR_STAT_CMD
0xA00 DSS_TPTC_A1_WR_BUS_SAFETY_ERR_STAT_WRITE
  fields as DSS_DSP_MDMA_BUS_SAFETY_ERR_STAT_CMD
0xA04 DSS_TPTC_A1_WR_BUS_SAFETY_ERR_STAT_WRITERESP
  fields as DSS_DSP_MDMA_BUS_SAFETY_ERR_STAT_CMD
0xA08 DSS_TPTC_B0_WR_BUS_SAFETY_CTRL access per field
  fields as DSS_DSP_MDMA_BUS_SAFETY_CTRL
0xA0C DSS_TPTC_B0_WR_BUS_SAFETY_FI rw
  fields as DSS_DSP_MDMA_BUS_SAFETY_FI
0xA10 DSS_TPTC_B0_WR_BUS_SAFETY_ERR
  fields as DSS_DSP_MDMA_BUS_SAFETY_ERR
0xA14 DSS_TPTC_B0_WR_BUS_SAFETY_ERR_STAT_DATA0
  fields as DSS_DSP_MDMA_BUS_SAFETY_ERR_STAT_DATA0
0xA18 DSS_TPTC_B0_WR_BUS_SAFETY_ERR_STAT_CMD
  fields as DSS_DSP_MDMA_BUS_SAFETY_ERR_STAT_CMD
0xA1C DSS_TPTC_B0_WR_BUS_SAFETY_ERR_STAT_WRITE
  fields as DSS_DSP_MDMA_BUS_SAFETY_ERR_STAT_CMD
0xA20 DSS_TPTC_B0_WR_BUS_SAFETY_ERR_STAT_WRITERESP
  fields as DSS_DSP_MDMA_BUS_SAFETY_ERR_STAT_CMD
0xA24 DSS_TPTC_B1_WR_BUS_SAFETY_CTRL access per field
  fields as DSS_DSP_MDMA_BUS_SAFETY_CTRL
0xA28 DSS_TPTC_B1_WR_BUS_SAFETY_FI rw
  fields as DSS_DSP_MDMA_BUS_SAFETY_FI
0xA2C DSS_TPTC_B1_WR_BUS_SAFETY_ERR
  fields as DSS_DSP_MDMA_BUS_SAFETY_ERR
0xA30 DSS_TPTC_B1_WR_BUS_SAFETY_ERR_STAT_DATA0
  fields as DSS_DSP_MDMA_BUS_SAFETY_ERR_STAT_DATA0
0xA34 DSS_TPTC_B1_WR_BUS_SAFETY_ERR_STAT_CMD
  fields as DSS_DSP_MDMA_BUS_SAFETY_ERR_STAT_CMD
0xA38 DSS_TPTC_B1_WR_BUS_SAFETY_ERR_STAT_WRITE
  fields as DSS_DSP_MDMA_BUS_SAFETY_ERR_STAT_CMD
0xA3C DSS_TPTC_B1_WR_BUS_SAFETY_ERR_STAT_WRITERESP
  fields as DSS_DSP_MDMA_BUS_SAFETY_ERR_STAT_CMD
{0xA40+0x1C*i} DSS_TPTC_C{i}_WR_BUS_SAFETY_CTRL access per field (i=0..5)
  fields as DSS_DSP_MDMA_BUS_SAFETY_CTRL
{0xA44+0x1C*i} DSS_TPTC_C{i}_WR_BUS_SAFETY_FI rw (i=0..5)
  fields as DSS_DSP_MDMA_BUS_SAFETY_FI
{0xA48+0x1C*i} DSS_TPTC_C{i}_WR_BUS_SAFETY_ERR (i=0..5)
  fields as DSS_DSP_MDMA_BUS_SAFETY_ERR
{0xA4C+0x1C*i} DSS_TPTC_C{i}_WR_BUS_SAFETY_ERR_STAT_DATA0 (i=0..5)
  fields as DSS_DSP_MDMA_BUS_SAFETY_ERR_STAT_DATA0
{0xA50+0x1C*i} DSS_TPTC_C{i}_WR_BUS_SAFETY_ERR_STAT_CMD (i=0..5)
  fields as DSS_DSP_MDMA_BUS_SAFETY_ERR_STAT_CMD
{0xA54+0x1C*i} DSS_TPTC_C{i}_WR_BUS_SAFETY_ERR_STAT_WRITE (i=0..5)
  fields as DSS_DSP_MDMA_BUS_SAFETY_ERR_STAT_CMD
{0xA58+0x1C*i} DSS_TPTC_C{i}_WR_BUS_SAFETY_ERR_STAT_WRITERESP (i=0..5)
  fields as DSS_DSP_MDMA_BUS_SAFETY_ERR_STAT_CMD
0xAE8 DSS_MDO_FIFO_BUS_SAFETY_CTRL access per field
  fields as DSS_DSP_MDMA_BUS_SAFETY_CTRL
0xAEC DSS_MDO_FIFO_BUS_SAFETY_FI rw
  fields as DSS_DSP_MDMA_BUS_SAFETY_FI
0xAF0 DSS_MDO_FIFO_BUS_SAFETY_ERR
  fields as DSS_DSP_MDMA_BUS_SAFETY_ERR
0xAF4 DSS_MDO_FIFO_BUS_SAFETY_ERR_STAT_DATA0
  fields as DSS_DSP_MDMA_BUS_SAFETY_ERR_STAT_DATA0
0xAF8 DSS_MDO_FIFO_BUS_SAFETY_ERR_STAT_CMD
  fields as DSS_DSP_MDMA_BUS_SAFETY_ERR_STAT_CMD
0xAFC DSS_MDO_FIFO_BUS_SAFETY_ERR_STAT_WRITE
  fields as DSS_DSP_MDMA_BUS_SAFETY_ERR_STAT_CMD
0xB00 DSS_MDO_FIFO_BUS_SAFETY_ERR_STAT_READ
  fields as DSS_DSP_MDMA_BUS_SAFETY_ERR_STAT_CMD
0xB04 DSS_MDO_FIFO_BUS_SAFETY_ERR_STAT_WRITERESP
  fields as DSS_DSP_MDMA_BUS_SAFETY_ERR_STAT_CMD
0xB08 DSS_CBUFF_FIFO_BUS_SAFETY_CTRL access per field
  fields as DSS_DSP_MDMA_BUS_SAFETY_CTRL
0xB0C DSS_CBUFF_FIFO_BUS_SAFETY_FI rw
  fields as DSS_DSP_MDMA_BUS_SAFETY_FI
0xB10 DSS_CBUFF_FIFO_BUS_SAFETY_ERR
  fields as DSS_DSP_MDMA_BUS_SAFETY_ERR
0xB14 DSS_CBUFF_FIFO_BUS_SAFETY_ERR_STAT_DATA0
  fields as DSS_DSP_MDMA_BUS_SAFETY_ERR_STAT_DATA0
0xB18 DSS_CBUFF_FIFO_BUS_SAFETY_ERR_STAT_CMD
  fields as DSS_DSP_MDMA_BUS_SAFETY_ERR_STAT_CMD
0xB1C DSS_CBUFF_FIFO_BUS_SAFETY_ERR_STAT_WRITE
  fields as DSS_DSP_MDMA_BUS_SAFETY_ERR_STAT_CMD
0xB20 DSS_CBUFF_FIFO_BUS_SAFETY_ERR_STAT_READ
  fields as DSS_DSP_MDMA_BUS_SAFETY_ERR_STAT_CMD
0xB24 DSS_CBUFF_FIFO_BUS_SAFETY_ERR_STAT_WRITERESP
  fields as DSS_DSP_MDMA_BUS_SAFETY_ERR_STAT_CMD
{0xB28+0x20*i} DSS_CMC_UCOMP{i}_BUS_SAFETY_CTRL access per field (i=0..3)
  fields as DSS_DSP_MDMA_BUS_SAFETY_CTRL
{0xB2C+0x20*i} DSS_CMC_UCOMP{i}_BUS_SAFETY_FI rw (i=0..3)
  fields as DSS_DSP_MDMA_BUS_SAFETY_FI
{0xB30+0x20*i} DSS_CMC_UCOMP{i}_BUS_SAFETY_ERR (i=0..3)
  fields as DSS_DSP_MDMA_BUS_SAFETY_ERR
{0xB34+0x20*i} DSS_CMC_UCOMP{i}_BUS_SAFETY_ERR_STAT_DATA0 (i=0..3)
  fields as DSS_DSP_MDMA_BUS_SAFETY_ERR_STAT_DATA0
{0xB38+0x20*i} DSS_CMC_UCOMP{i}_BUS_SAFETY_ERR_STAT_CMD (i=0..3)
  fields as DSS_DSP_MDMA_BUS_SAFETY_ERR_STAT_CMD
{0xB3C+0x20*i} DSS_CMC_UCOMP{i}_BUS_SAFETY_ERR_STAT_WRITE (i=0..3)
  fields as DSS_DSP_MDMA_BUS_SAFETY_ERR_STAT_CMD
{0xB40+0x20*i} DSS_CMC_UCOMP{i}_BUS_SAFETY_ERR_STAT_READ (i=0..3)
  fields as DSS_DSP_MDMA_BUS_SAFETY_ERR_STAT_CMD
{0xB44+0x20*i} DSS_CMC_UCOMP{i}_BUS_SAFETY_ERR_STAT_WRITERESP (i=0..3)
  fields as DSS_DSP_MDMA_BUS_SAFETY_ERR_STAT_CMD
0xBA8 DSS_CMC_COMP_BUS_SAFETY_CTRL access per field
  fields as DSS_DSP_MDMA_BUS_SAFETY_CTRL
0xBAC DSS_CMC_COMP_BUS_SAFETY_FI rw
  fields as DSS_DSP_MDMA_BUS_SAFETY_FI
0xBB0 DSS_CMC_COMP_BUS_SAFETY_ERR
  fields as DSS_DSP_MDMA_BUS_SAFETY_ERR
0xBB4 DSS_CMC_COMP_BUS_SAFETY_ERR_STAT_DATA0
  fields as DSS_DSP_MDMA_BUS_SAFETY_ERR_STAT_DATA0
0xBB8 DSS_CMC_COMP_BUS_SAFETY_ERR_STAT_CMD
  fields as DSS_DSP_MDMA_BUS_SAFETY_ERR_STAT_CMD
0xBBC DSS_CMC_COMP_BUS_SAFETY_ERR_STAT_WRITE
  fields as DSS_DSP_MDMA_BUS_SAFETY_ERR_STAT_CMD
0xBC0 DSS_CMC_COMP_BUS_SAFETY_ERR_STAT_READ
  fields as DSS_DSP_MDMA_BUS_SAFETY_ERR_STAT_CMD
0xBC4 DSS_CMC_COMP_BUS_SAFETY_ERR_STAT_WRITERESP
  fields as DSS_DSP_MDMA_BUS_SAFETY_ERR_STAT_CMD
0xBC8 DSS_MCRC_BUS_SAFETY_CTRL access per field
  fields as DSS_DSP_MDMA_BUS_SAFETY_CTRL
0xBCC DSS_MCRC_BUS_SAFETY_FI rw
  fields as DSS_DSP_MDMA_BUS_SAFETY_FI
0xBD0 DSS_MCRC_BUS_SAFETY_ERR
  fields as DSS_DSP_MDMA_BUS_SAFETY_ERR
0xBD4 DSS_MCRC_BUS_SAFETY_ERR_STAT_DATA0
  fields as DSS_DSP_MDMA_BUS_SAFETY_ERR_STAT_DATA0
0xBD8 DSS_MCRC_BUS_SAFETY_ERR_STAT_CMD
  fields as DSS_DSP_MDMA_BUS_SAFETY_ERR_STAT_CMD
0xBDC DSS_MCRC_BUS_SAFETY_ERR_STAT_WRITE
  fields as DSS_DSP_MDMA_BUS_SAFETY_ERR_STAT_CMD
0xBE0 DSS_MCRC_BUS_SAFETY_ERR_STAT_READ
  fields as DSS_DSP_MDMA_BUS_SAFETY_ERR_STAT_CMD
0xBE4 DSS_MCRC_BUS_SAFETY_ERR_STAT_WRITERESP
  fields as DSS_DSP_MDMA_BUS_SAFETY_ERR_STAT_CMD
0xBE8 DSS_PCR_BUS_SAFETY_CTRL access per field
  fields as DSS_DSP_MDMA_BUS_SAFETY_CTRL
0xBEC DSS_PCR_BUS_SAFETY_FI rw
  fields as DSS_DSP_MDMA_BUS_SAFETY_FI
0xBF0 DSS_PCR_BUS_SAFETY_ERR
  fields as DSS_DSP_MDMA_BUS_SAFETY_ERR
0xBF4 DSS_PCR_BUS_SAFETY_ERR_STAT_DATA0
  fields as DSS_DSP_MDMA_BUS_SAFETY_ERR_STAT_DATA0
0xBF8 DSS_PCR_BUS_SAFETY_ERR_STAT_CMD
  fields as DSS_DSP_MDMA_BUS_SAFETY_ERR_STAT_CMD
0xBFC DSS_PCR_BUS_SAFETY_ERR_STAT_WRITE
  fields as DSS_DSP_MDMA_BUS_SAFETY_ERR_STAT_CMD
0xC00 DSS_PCR_BUS_SAFETY_ERR_STAT_READ
  fields as DSS_DSP_MDMA_BUS_SAFETY_ERR_STAT_CMD
0xC04 DSS_PCR_BUS_SAFETY_ERR_STAT_WRITERESP
  fields as DSS_DSP_MDMA_BUS_SAFETY_ERR_STAT_CMD
0xC08 DSS_HWA_DMA0_BUS_SAFETY_CTRL access per field
  fields as DSS_DSP_MDMA_BUS_SAFETY_CTRL
0xC0C DSS_HWA_DMA0_BUS_SAFETY_FI rw
  fields as DSS_DSP_MDMA_BUS_SAFETY_FI
0xC10 DSS_HWA_DMA0_BUS_SAFETY_ERR
  fields as DSS_DSP_MDMA_BUS_SAFETY_ERR
0xC14 DSS_HWA_DMA0_BUS_SAFETY_ERR_STAT_DATA0
  fields as DSS_DSP_MDMA_BUS_SAFETY_ERR_STAT_DATA0
0xC18 DSS_HWA_DMA0_BUS_SAFETY_ERR_STAT_CMD
  fields as DSS_DSP_MDMA_BUS_SAFETY_ERR_STAT_CMD
0xC1C DSS_HWA_DMA0_BUS_SAFETY_ERR_STAT_WRITE
  fields as DSS_DSP_MDMA_BUS_SAFETY_ERR_STAT_CMD
0xC20 DSS_HWA_DMA0_BUS_SAFETY_ERR_STAT_READ
  fields as DSS_DSP_MDMA_BUS_SAFETY_ERR_STAT_CMD
0xC24 DSS_HWA_DMA0_BUS_SAFETY_ERR_STAT_WRITERESP
  fields as DSS_DSP_MDMA_BUS_SAFETY_ERR_STAT_CMD
0xC28 DSS_HWA_DMA1_BUS_SAFETY_CTRL access per field
  fields as DSS_DSP_MDMA_BUS_SAFETY_CTRL
0xC2C DSS_HWA_DMA1_BUS_SAFETY_FI rw
  fields as DSS_DSP_MDMA_BUS_SAFETY_FI
0xC30 DSS_HWA_DMA1_BUS_SAFETY_ERR
  fields as DSS_DSP_MDMA_BUS_SAFETY_ERR
0xC34 DSS_HWA_DMA1_BUS_SAFETY_ERR_STAT_DATA0
  fields as DSS_DSP_MDMA_BUS_SAFETY_ERR_STAT_DATA0
0xC38 DSS_HWA_DMA1_BUS_SAFETY_ERR_STAT_CMD
  fields as DSS_DSP_MDMA_BUS_SAFETY_ERR_STAT_CMD
0xC3C DSS_HWA_DMA1_BUS_SAFETY_ERR_STAT_WRITE
  fields as DSS_DSP_MDMA_BUS_SAFETY_ERR_STAT_CMD
0xC40 DSS_HWA_DMA1_BUS_SAFETY_ERR_STAT_READ
  fields as DSS_DSP_MDMA_BUS_SAFETY_ERR_STAT_CMD
0xC44 DSS_HWA_DMA1_BUS_SAFETY_ERR_STAT_WRITERESP
  fields as DSS_DSP_MDMA_BUS_SAFETY_ERR_STAT_CMD
0xC48 DSS_CM4_M_BUS_SAFETY_CTRL access per field
  fields as DSS_DSP_MDMA_BUS_SAFETY_CTRL
0xC4C DSS_CM4_M_BUS_SAFETY_FI rw
  fields as DSS_DSP_MDMA_BUS_SAFETY_FI
0xC50 DSS_CM4_M_BUS_SAFETY_ERR
  fields as DSS_DSP_MDMA_BUS_SAFETY_ERR
0xC54 DSS_CM4_M_BUS_SAFETY_ERR_STAT_DATA0
  fields as DSS_DSP_MDMA_BUS_SAFETY_ERR_STAT_DATA0
0xC58 DSS_CM4_M_BUS_SAFETY_ERR_STAT_CMD
  fields as DSS_DSP_MDMA_BUS_SAFETY_ERR_STAT_CMD
0xC5C DSS_CM4_M_BUS_SAFETY_ERR_STAT_WRITE
  fields as DSS_DSP_MDMA_BUS_SAFETY_ERR_STAT_CMD
0xC60 DSS_CM4_M_BUS_SAFETY_ERR_STAT_READ
  fields as DSS_DSP_MDMA_BUS_SAFETY_ERR_STAT_CMD
0xC64 DSS_CM4_M_BUS_SAFETY_ERR_STAT_WRITERESP
  fields as DSS_DSP_MDMA_BUS_SAFETY_ERR_STAT_CMD
0xC68 DSS_CM4_S_BUS_SAFETY_CTRL access per field
  fields as DSS_DSP_MDMA_BUS_SAFETY_CTRL
0xC6C DSS_CM4_S_BUS_SAFETY_FI rw
  fields as DSS_DSP_MDMA_BUS_SAFETY_FI
0xC70 DSS_CM4_S_BUS_SAFETY_ERR
  fields as DSS_DSP_MDMA_BUS_SAFETY_ERR
0xC74 DSS_CM4_S_BUS_SAFETY_ERR_STAT_DATA0
  fields as DSS_DSP_MDMA_BUS_SAFETY_ERR_STAT_DATA0
0xC78 DSS_CM4_S_BUS_SAFETY_ERR_STAT_CMD
  fields as DSS_DSP_MDMA_BUS_SAFETY_ERR_STAT_CMD
0xC7C DSS_CM4_S_BUS_SAFETY_ERR_STAT_WRITE
  fields as DSS_DSP_MDMA_BUS_SAFETY_ERR_STAT_CMD
0xC80 DSS_CM4_S_BUS_SAFETY_ERR_STAT_READ
  fields as DSS_DSP_MDMA_BUS_SAFETY_ERR_STAT_CMD
0xC84 DSS_CM4_S_BUS_SAFETY_ERR_STAT_WRITERESP
  fields as DSS_DSP_MDMA_BUS_SAFETY_ERR_STAT_CMD
0xC88 DSS_MBOX_BUS_SAFETY_CTRL access per field
  fields as DSS_DSP_MDMA_BUS_SAFETY_CTRL
0xC8C DSS_MBOX_BUS_SAFETY_FI rw
  fields as DSS_DSP_MDMA_BUS_SAFETY_FI
0xC90 DSS_MBOX_BUS_SAFETY_ERR
  fields as DSS_DSP_MDMA_BUS_SAFETY_ERR
0xC94 DSS_MBOX_BUS_SAFETY_ERR_STAT_DATA0
  fields as DSS_DSP_MDMA_BUS_SAFETY_ERR_STAT_DATA0
0xC98 DSS_MBOX_BUS_SAFETY_ERR_STAT_CMD
  fields as DSS_DSP_MDMA_BUS_SAFETY_ERR_STAT_CMD
0xC9C DSS_MBOX_BUS_SAFETY_ERR_STAT_WRITE
  fields as DSS_DSP_MDMA_BUS_SAFETY_ERR_STAT_CMD
0xCA0 DSS_MBOX_BUS_SAFETY_ERR_STAT_READ
  fields as DSS_DSP_MDMA_BUS_SAFETY_ERR_STAT_CMD
0xCA4 DSS_MBOX_BUS_SAFETY_ERR_STAT_WRITERESP
  fields as DSS_DSP_MDMA_BUS_SAFETY_ERR_STAT_CMD
{0xFD0+4i} HW_SPARE_RW{i} rw (i=0..3)
  [31:0] hw_spare_rw{i} — Reserved for HW R&D
{0xFE0+4i} HW_SPARE_RO{i} (i=0..3)
  [31:0] hw_spare_ro{i} — Reserved for HW R&D
0xFF0 HW_SPARE_WPH rw
  [31:0] proc — Write pulse bit field: For bits 0 to 7: Wrting 1'b1 : Generates pulse interrupt to corresponding proc from DSP.
0xFF4 HW_SPARE_REC rw
  [n] hw_spare_rec{n} (n=0..31) — Reserved for HW R&D
0x1008 LOCK0_KICK0 rw — - KICK0 component
  [31:0] ?
0x100C LOCK0_KICK1 rw — - KICK1 component
  [31:0] ?
0x1010 intr_raw_status rw — Interrupt Raw Status/Set Register
  [3] ? — Proxy0 access violation error. Raw status is read. Write a 1 to set the status. Writing a 0 has no effect.
  [2] ? — Kick access violation error. Raw status is read. Write a 1 to set the status. Writing a 0 has no effect.
  [1] ? — Addressing violation error. Raw status is read. Write a 1 to set the status. Writing a 0 has no effect.
  [0] ? — Protection violation error. Raw status is read. Write a 1 to set the status. Writing a 0 has no effect.
0x1014 intr_enabled_status_clear rw — Interrupt Enabled Status/Clear register
  [3] ? — Proxy0 access violation error. Enabled status is read. Write a 1 to clear the status. Writing a 0 has no effect.
  [2] ? — Kick access violation error. Enabled status is read. Write a 1 to clear the status. Writing a 0 has no effect.
  [1] ? — Addressing violation error. Enabled status is read. Write a 1 to clear the status. Writing a 0 has no effect.
  [0] ? — Protection violation error. Enabled status is read. Write a 1 to clear the status. Writing a 0 has no effect.
0x1018 intr_enable rw — Interrupt Enable register
  [3] ? — Proxy0 access violation error enable. Write a 1 to set the enable. Writing a 0 has no effect.
  [2] ? — Kick access violation error enable. Write a 1 to set the enable. Writing a 0 has no effect.
  [1] ? — Addressing violation error enable. Write a 1 to set the enable. Writing a 0 has no effect.
  [0] ? — Protection violation error enable. Write a 1 to set the enable. Writing a 0 has no effect.
0x101C intr_enable_clear rw — Interrupt Enable Clear register
  [3] ? — Proxy0 access violation error enable clear. Write a 1 to clear the enable. Writing a 0 has no effect.
  [2] ? — Kick access violation error enable clear. Write a 1 to clear the enable. Writing a 0 has no effect.
  [1] ? — Addressing violation error enable clear. Write a 1 to clear the enable. Writing a 0 has no effect.
  [0] ? — Protection violation error enable clear. Write a 1 to clear the enable. Writing a 0 has no effect.
0x1020 eoi rw
  [7:0] ? — EOI vector value. Write this with interrupt distribution value in the chip.
0x1024 fault_address
  [31:0] ? — Fault Address.
0x1028 fault_type_status
  [6] ? — Non-secure access.
  [5:0] ? — Fault Type 10_0000 = Supervisor read fault - priv = 1 dir = 1 dtype != 1 01_0000 = Supervisor write fault - priv = 1 dir = 0 00_1000 = Supervisor execute fault - priv = 1 dir = 1 dtype = 1 00_0100 = User read fault - priv = 0 dir = 1 dtype = 1 00_0010 = User write fault - priv = 0 dir = 0 00_0001 = User execute fault - priv = 0 dir = 1 dtype = 1 00_0000 = No fault
0x102C fault_attr_status — Fault Attribute Status register
  [31:20] ? — XID.
  [19:8] ? — Route ID.
  [7:0] ? — Privilege ID.
0x1030 fault_clear wo
  [0] ? — Fault clear. Writing a 1 clears the current fault. Writing a 0 has no effect.
